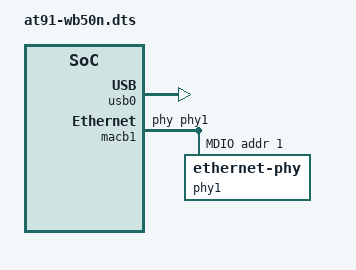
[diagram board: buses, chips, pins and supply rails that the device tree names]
// SPDX-License-Identifier: GPL-2.0
/*
 * at91-wb50n.dts - Device Tree file for WB50N evaluation board
 *
 * Copyright (C) 2018-2020 Laird Connectivity
 *
 */

/dts-v1/;

#include "at91-wb50n.dtsi"

&usb0 {
	status = "okay";
};

&macb1 {
	status = "okay";

	phy-handle = <&phy1>;

	mdio {
		#address-cells = <1>;
		#size-cells = <0>;

		phy1: ethernet-phy@1 {
			reg = <1>;
		};
	};
};
